# WS63 register map
File version: 1.0
CPU: other r0p0, little endian, MPU, FPU, 3 interrupt priority bits
Registers are 32-bit, read-write, reset 0x0 unless marked. A register's access mark holds for its fields unless they carry their own. Offsets are from the block's base; [hi:lo] are bit positions.

## CMU — Clock management unit registers used by WS63 clock and PLL setup
Base 0x40003000
0x134 RF_RX_LDO — RF receiver 1.0 V LDO control used by the application-owned RF power-up sequence
  [15:0] control — Complete vendor-defined RF RX LDO control value
0x138 RF_LNA_LDO — RF low-noise amplifier 1.0 V LDO control
  [15:0] control — Complete vendor-defined RF LNA LDO control value
0x140 RF_VCO_LDO — RF voltage-controlled oscillator 1.0 V LDO control
  [15:0] control — Complete vendor-defined RF VCO LDO control value
0x144 RF_ABB_LDO — RF analog-baseband 1.0 V LDO control
  [15:0] control — Complete vendor-defined RF analog-baseband LDO control value
0x148 RF_PLL_LDO — RF phase-locked-loop 1.0 V LDO control
  [15:0] control — Complete vendor-defined RF PLL LDO control value
0x168 RF_TX_LDO — RF transmitter 1.8 V LDO control
  [15:0] control — Complete vendor-defined RF TX LDO control value
0x19C EXCEP_RO_RG ro — Exception read-only status register
  [12] fnpll_lock_grm — FNPLL lock status queried by the vendor cmu_is_fnpll_locked path
0x230 RF_ADDA_ISO — RF ADC/DAC isolation release control
  [1:0] control — RF ADC/DAC isolation control value
0x400 RF_PLL_REFERENCE — RF PLL reference-clock enable control
  [2:0] control — Complete vendor-defined RF PLL reference control value
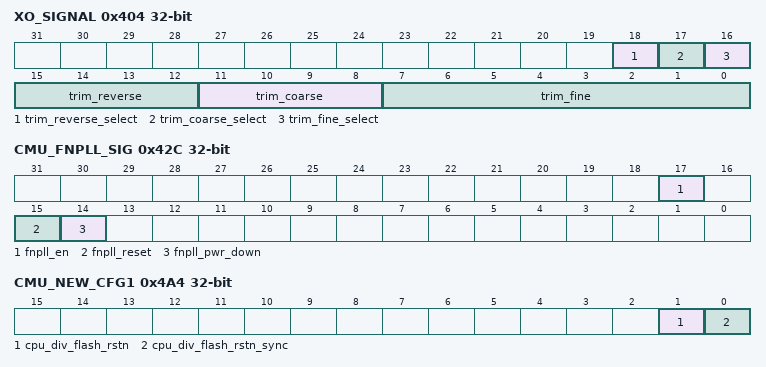
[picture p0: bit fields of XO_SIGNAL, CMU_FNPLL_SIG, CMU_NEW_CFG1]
0x404 XO_SIGNAL — Crystal-oscillator trim and signal control
  [18] trim_reverse_select — Use the programmed reverse trim code
  [17] trim_coarse_select — Use the programmed coarse trim code
  [16] trim_fine_select — Use the programmed fine trim code
  [15:12] trim_reverse — Crystal oscillator reverse trim code
  [11:8] trim_coarse — Crystal oscillator coarse trim code
  [7:0] trim_fine — Crystal oscillator fine trim code
0x42C CMU_FNPLL_SIG — FNPLL signal and control register
  [17] fnpll_en — FNPLL enable bit used by the vendor PM path
  [15] fnpll_reset — FNPLL reset/control bit used by the vendor PM path
  [14] fnpll_pwr_down — FNPLL power-down control used by the vendor PM path
0x4A0 CMU_NEW_CFG0 — CMU divider reset-sync control 0
  [0] cmu_div_ad_rstn_sync — I2S/SIO divider reset-sync release bit used by sio_porting_clock_enable
0x4A4 CMU_NEW_CFG1 — CMU flash/CPU divider reset control
  [1] cpu_div_flash_rstn — Flash divider reset release bit written before switching flash clock to PLL
  [0] cpu_div_flash_rstn_sync — Flash divider reset-sync bit written before switching flash clock to PLL

## GLB_CTL_M — Main core global control - BCPU/MCPU reset status, chip reset, AON CRG
Base 0x40002000
0x30 BCPU_RESET_STS — BCPU reset status register
  [31:0] bcpu_reset_sts ro — BCPU reset status
0x34 MCPU_RESET_STS — MCPU reset status register
  [31:0] mcpu_reset_sts ro — MCPU reset status
0x3C RESET_STS_CLEAR wo — Reset status clear register
  [31:0] rst_sts_clear — Write 0xFF to clear all reset status bits
0x100 AON_CRG_CKEN_CTL — AON CRG clock enable control
  [4] wdt_gate — WDT clock gate control at bit[4]
0x110 CHIP_RESET — Chip reset control register
  [2] chip_reset_en — Chip reset enable: 1=assert chip reset
0x110 AON_SOFT_RST_CTL — AON soft reset control
  [1] wdt_soft_rst — WDT soft reset at bit[1]

## PKE — Public Key Engine - modular arithmetic accelerator
Base 0x44110000
0x00 PKE_WORK_LEN — PKE work length register
  [31:0] work_len — Operand bit length for modular arithmetic
0x04 PKE_INSTR0 — PKE instruction register 0
  [31:0] instr0 — Instruction code 0 (0=MUL_MOD, 1=ADD_MOD, 2=SUB_MOD)
    0=MUL_MOD (Modular multiplication); 1=ADD_MOD (Modular addition); 2=SUB_MOD (Modular subtraction)
0x08 PKE_INSTR1 — PKE instruction register 1
  [31:0] instr1 — Instruction code 1
0x0C PKE_INSTR_ADDR_LOW — PKE instruction start address low
  [31:0] instr_addr_low — Instruction start address [31:0]
0x10 PKE_INSTR_ADDR_HIG — PKE instruction start address high
  [31:0] instr_addr_hig — Instruction start address high bits
0x14 PKE_INSTR_LEN — PKE instruction length
  [31:0] instr_len — Total instruction length in bytes
0x18 PKE_MASK_RNG_CFG — PKE mask RNG configuration
  [0] mask_rng_cfg — Mask RNG enable: 0=disabled; 1=enabled
0x20 PKE_MONT_PARA0 — PKE Montgomery parameter 0
  [31:0] mont_para0 — Montgomery pre-computed parameter word 0
0x24 PKE_MONT_PARA1 — PKE Montgomery parameter 1
  [31:0] mont_para1 — Montgomery pre-computed parameter word 1
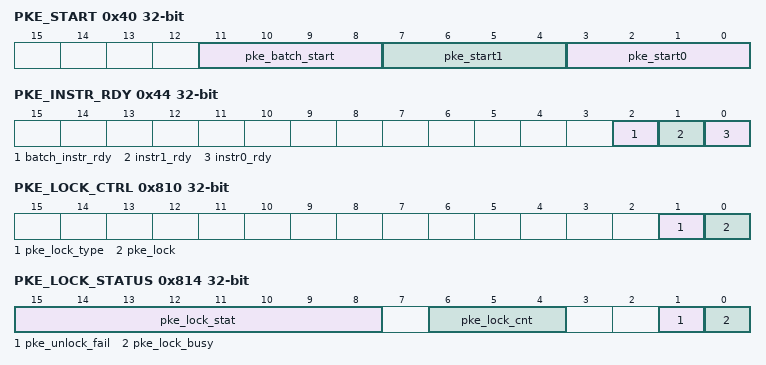
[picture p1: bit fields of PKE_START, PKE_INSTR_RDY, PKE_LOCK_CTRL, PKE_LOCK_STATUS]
0x40 PKE_START — PKE start control register
  [11:8] pke_batch_start wo — Batch start code (write 0x5)
  [7:4] pke_start1 wo — Start code 1 (write 0xA)
    10=StartCode (Must write 0xA to start PKE operation)
  [3:0] pke_start0 wo — Start code 0 (write 0x5 to start)
    5=StartCode (Must write 0x5 to start PKE operation)
0x44 PKE_INSTR_RDY — PKE instruction ready status
  [2] batch_instr_rdy ro — Batch instruction ready
  [1] instr1_rdy ro — Instruction buffer 1 ready
  [0] instr0_rdy ro — Instruction buffer 0 ready
0x48 PKE_BUSY — PKE busy status register
  [0] pke_busy ro — PKE busy: 0=idle; 1=busy
0x4C PKE_NOISE_EN — PKE noise enable register
  [0] noise_en — Side-channel noise enable
0x80 PKE_INT_ENABLE — PKE interrupt enable
  [0] finish_int_enable — Operation finish interrupt enable
0x84 PKE_INT_NOMASK_STATUS — PKE unmasked interrupt status; write the observed finish code to clear
  [3:0] finish_int_nomask — Finish interrupt status (expect 0x5 after completion)
0x8C PKE_ALARM_STATUS — PKE alarm status register; the documented clean code is writable
  [3:0] alarm_int — Security alarm interrupt
0x90 PKE_FAILURE_FLAG
  [10:0] pke_failure_flag ro — Operation failure status
0xC0 PKE_DRAM_CLR — PKE DRAM clear register
  [0] dram_clr wo — Clear PKE DRAM
0xF0 PKE_DRAM_MASK — Mask word XORed with every PKE data-RAM word
  [31:0] dram_mask — Current PKE data-RAM mask word
0x810 PKE_LOCK_CTRL — PKE lock control register
  [1] pke_lock_type — Lock type: 0=soft; 1=hard
  [0] pke_lock — Lock request
0x814 PKE_LOCK_STATUS
  [15:8] pke_lock_stat ro — Lock status: 0x6A=PCPU; 0x35=AIDSP; 0xA5=TEE; 0xAA=ACPU
  [6:4] pke_lock_cnt ro — Lock count
  [1] pke_unlock_fail ro — Unlock failure flag
  [0] pke_lock_busy ro — Lock busy flag
